# AVR128DB64 device description
Architecture: AVR8X; Family: AVR
Registers are 8-bit, read-write, reset 0x0 unless marked. A register's access mark holds for its fields unless they carry their own. Offsets are from the block's base; [hi:lo] are bit positions.

## PORTMUX — Port Multiplexer
Instances: PORTMUX 0x05E0
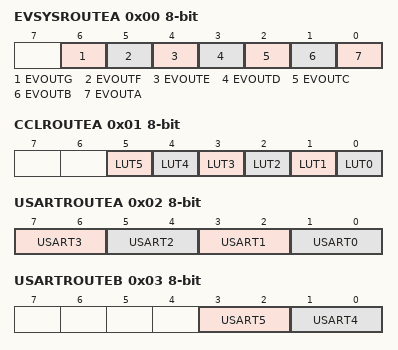
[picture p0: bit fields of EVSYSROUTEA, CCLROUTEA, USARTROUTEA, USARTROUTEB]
0x00 EVSYSROUTEA
  [6] EVOUTG — Event Output G
    0=DEFAULT (EVOUT on PG2); 1=ALT1 (EVOUT on PG7)
  [5] EVOUTF — Event Output F
    0=DEFAULT (EVOUT on PF2)
  [4] EVOUTE — Event Output E
    0=DEFAULT (EVOUT on PE2); 1=ALT1 (EVOUT on PE7)
  [3] EVOUTD — Event Output D
    0=DEFAULT (EVOUT on PD2); 1=ALT1 (EVOUT on PD7)
  [2] EVOUTC — Event Output C
    0=DEFAULT (EVOUT on PC2); 1=ALT1 (EVOUT on PC7)
  [1] EVOUTB — Event Output B
    0=DEFAULT (EVOUT on PB2); 1=ALT1 (EVOUT on PB7)
  [0] EVOUTA — Event Output A
    0=DEFAULT (EVOUT on PA2); 1=ALT1 (EVOUT on PA7)
0x01 CCLROUTEA
  [5] LUT5 — CCL Look-Up Table 5 Signals
    0=DEFAULT (Out: PG3 In: PG0, PG1, PG2); 1=ALT1 (Out: PG6 In: PG0, PG1, PG2)
  [4] LUT4 — CCL Look-Up Table 4 Signals
    0=DEFAULT (Out: PB3 In: PB0, PB1, PB2); 1=ALT1 (Out: PB6 In: PB0, PB1, PB2)
  [3] LUT3 — CCL Look-Up Table 3 Signals
    0=DEFAULT (Out: PF3 In: PF0, PF1, PF2)
  [2] LUT2 — CCL Look-Up Table 2 Signals
    0=DEFAULT (Out: PD3 In: PD0, PD1, PD2); 1=ALT1 (Out: PD6 In: PD0, PD1, PD2)
  [1] LUT1 — CCL Look-Up Table 1 Signals
    0=DEFAULT (Out: PC3 In: PC0, PC1, PC2); 1=ALT1 (Out: PC6 In: PC0, PC1, PC2)
  [0] LUT0 — CCL Look-Up Table 0 Signals
    0=DEFAULT (Out: PA3 In: PA0, PA1, PA2); 1=ALT1 (Out: PA6 In: PA0, PA1, PA2)
0x02 USARTROUTEA
  [7:6] USART3 — USART3 Signals
    0=DEFAULT (PB0, PB1, PB2, PB3); 1=ALT1 (PB4, PB5, PB6, PB7); 3=NONE (Not connected to any pins)
  [5:4] USART2 — USART2 Signals
    0=DEFAULT (PF0, PF1, PF2, PF3); 1=ALT1 (PF4, PF5); 3=NONE (Not connected to any pins)
  [3:2] USART1 — USART1 Signals
    0=DEFAULT (PC0, PC1, PC2, PC3); 1=ALT1 (PC4, PC5, PC6, PC7); 3=NONE (Not connected to any pins)
  [1:0] USART0 — USART0 Signals
    0=DEFAULT (PA0, PA1, PA2, PA3); 1=ALT1 (PA4, PA5, PA6, PA7); 3=NONE (Not connected to any pins)
0x03 USARTROUTEB
  [3:2] USART5 — USART5 Signals
    0=DEFAULT (PG0, PG1, PG2, PG3); 1=ALT1 (PG4, PG5, PG6, PG7); 3=NONE (Not connected to any pins)
  [1:0] USART4 — USART4 Signals
    0=DEFAULT (PE0, PE1, PE2, PE3); 1=ALT1 (PE4, PE5, PE6, PE7); 3=NONE (Not connected to any pins)
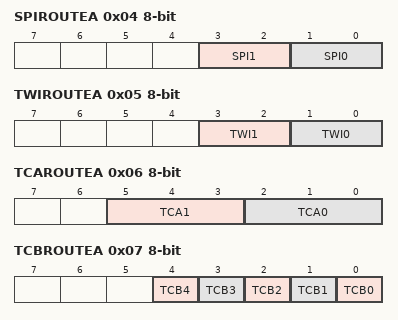
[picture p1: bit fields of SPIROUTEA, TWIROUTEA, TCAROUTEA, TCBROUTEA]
0x04 SPIROUTEA
  [3:2] SPI1 — SPI1 Signals
    0=DEFAULT (PC0, PC1, PC2, PC3); 1=ALT1 (PC4, PC5, PC6, PC7); 2=ALT2 (PB4, PB5, PB6, PB7); 3=NONE (Not connected to any pins)
  [1:0] SPI0 — SPI0 Signals
    0=DEFAULT (PA4, PA5, PA6, PA7); 1=ALT1 (PE0, PE1, PE2, PE3); 2=ALT2 (PG4, PG5, PG6, PG7); 3=NONE (Not connected to any pins)
0x05 TWIROUTEA
  [3:2] TWI1 — TWI1 Signals
    0=DEFAULT (PF2, PF3, PB2, PB3); 1=ALT1 (PF2, PF3, PB6, PB7); 2=ALT2 (PB2, PB3, PB6, PB7)
  [1:0] TWI0 — TWI0 Signals
    0=DEFAULT (PA2, PA3, PC2, PC3); 1=ALT1 (PA2, PA3, PC6, PC7); 2=ALT2 (PC2, PC3, PC6, PC7)
0x06 TCAROUTEA
  [5:3] TCA1 — TCA1 Signals
    0=PORTB (PB0, PB1, PB2, PB3, PB4, PB5); 1=PORTC (PC4, PC5, PC6); 2=PORTE (PE4, PE5, PE6); 3=PORTG (PG0, PG1, PG2, PG3, PG4, PG5)
  [2:0] TCA0 — TCA0 Signals
    0=PORTA (PA0, PA1, PA2, PA3, PA4, PA5); 1=PORTB (PB0, PB1, PB2, PB3, PB4, PB5); 2=PORTC (PC0, PC1, PC2, PC3, PC4, PC5); 3=PORTD (PD0, PD1, PD2, PD3, PD4, PD5); 4=PORTE (PE0, PE1, PE2, PE3, PE4, PE5); 5=PORTF (PF0, PF1, PF2, PF3, PF4, PF5); 6=PORTG (PG0, PG1, PG2, PG3, PG4, PG5)
0x07 TCBROUTEA
  [4] TCB4 — TCB4 Output
    0=DEFAULT (WO on PG3); 1=ALT1 (WO on PC6)
  [3] TCB3 — TCB3 Output
    0=DEFAULT (WO on PB5); 1=ALT1 (WO on PC1)
  [2] TCB2 — TCB2 Output
    0=DEFAULT (WO on PC0); 1=ALT1 (WO on PB4)
  [1] TCB1 — TCB1 Output
    0=DEFAULT (WO on PA3); 1=ALT1 (WO on PF5)
  [0] TCB0 — TCB0 Output
    0=DEFAULT (WO on PA2); 1=ALT1 (WO on PF4)
0x08 TCDROUTEA
  [2:0] TCD0 — TCD0 Signals
    0=DEFAULT (PA4, PA5, PA6, PA7); 1=ALT1 (PB4, PB5, PB6, PB7); 2=ALT2 (PF0, PF1, PF2, PF3); 3=ALT3 (PG4, PG5, PG6, PG7)
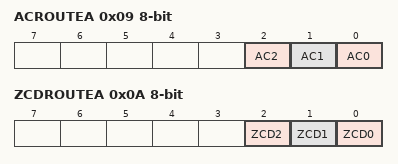
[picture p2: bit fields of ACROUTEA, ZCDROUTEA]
0x09 ACROUTEA
  [all] fields
    0=DEFAULT (OUT on PA7); 1=ALT1 (OUT on PC6)
  [2] AC2 — Analog Comparator 2 Output
  [1] AC1 — Analog Comparator 1 Output
  [0] AC0 — Analog Comparator 0 Output
0x0A ZCDROUTEA
  [all] fields
    0=DEFAULT (OUT on PA7); 1=ALT1 (OUT on PC7)
  [2] ZCD2 — Zero Cross Detector 2 Output
  [1] ZCD1 — Zero Cross Detector 1 Output
  [0] ZCD0 — Zero Cross Detector 0 Output
